# STM32N657xx register map
File version: 1.0
Registers are 32-bit, read-write, reset 0x0 unless marked. A register's access mark holds for its fields unless they carry their own. Offsets are from the block's base; [hi:lo] are bit positions; {n}, {i} and the like mark numbered series.

## PWR — Power Control
Base 0x46024800
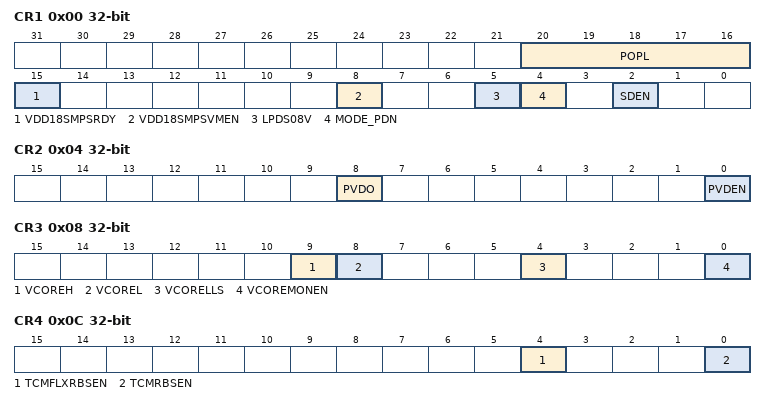
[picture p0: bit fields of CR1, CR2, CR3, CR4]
0x00 CR1 — PWR Control register 1
  [20:16] POPL — pwr_on pulse low configuration
  [15] VDD18SMPSRDY — VDD18SMPS ready
  [8] VDD18SMPSVMEN — VDD18SMPS voltage monitor enable
  [5] LPDS08V — SMPS Low power mode enable (SVOS high only)
  [4] MODE_PDN — Pull down on output voltage during power down mode
  [2] SDEN — SMPS step-down converter enable
    1=SMPS_SUPPLY (Core domains are supplied from the SMPS); 0=EXTERNAL_SOURCE_SUPPLY (The SMPS is Bypassed. The Core domains are supplied from an external source)
0x04 CR2 — PWR Control Register 2
  [8] PVDO — Programmable Voltage Detect Output
  [0] PVDEN — Programmable Voltage detector enable
0x08 CR3 — PWR Control Register 3
  [9] VCOREH — Monitored VDDCORE level above high threshold
  [8] VCOREL — Monitored VDDCORE level above low threshold
  [4] VCORELLS — VDDCORE Voltage Detector low level selection
    0=SCALE1 (VDDCORE low-voltage threshold 1 selected (VOS 1)); 1=SCALE0 (VDDCORE low-voltage threshold 2 selected (VOS 0))
  [0] VCOREMONEN — VDDCORE monitoring enable
0x0C CR4 — PWR Control Register 4
  [4] TCMFLXRBSEN — I-TCM FLEX MEM backup supply enable (used to maintain I-TCM FLEX MEM content in Standby mode)
  [0] TCMRBSEN — I-TCM and D-TCM RAMs backup supply enable (used to maintain TCM RAMs content in Standby mode)
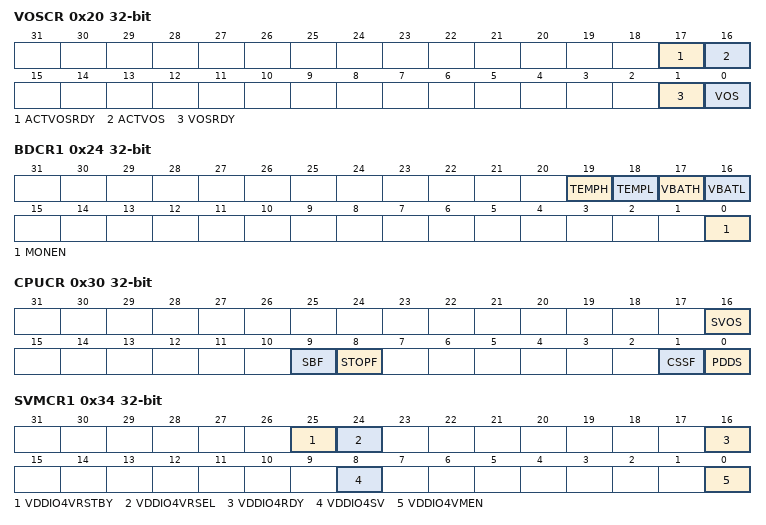
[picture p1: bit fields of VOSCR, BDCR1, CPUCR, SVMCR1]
0x20 VOSCR — PWR Voltage scaling control register
  [17] ACTVOSRDY — Voltage levels ready bit for currently used ACTVOS
  [16] ACTVOS — VOS currently applied for VCORE voltage scaling selection
  [1] VOSRDY — VOS Ready bit for VCORE voltage scaling output selection
  [0] VOS — Voltage scaling selection according to performance
    1=SCALE0 (Voltage scaling range 0 (highest frequency)); 0=SCALE1 (Voltage scaling range 1 (lowest power))
0x24 BDCR1 — PWR Backup domain control register 1
  [19] TEMPH — Temperature level monitoring versus high threshold
  [18] TEMPL — Temperature level monitoring versus low threshold
  [17] VBATH — VBAT level monitoring versus high threshold
  [16] VBATL — VBAT level monitoring versus low threshold
  [0] MONEN — VBAT and temperature monitoring enable
0x28 BDCR2 — PWR Backup domain control register 2
  [0] BKPRBSEN — Backup RAM backup supply enable (used to maintain BKP RAM content in Standby and VBAT modes)
0x2C DBPCR — PWR Disable backup protection control register
  [0] DBP — Disable backup domain write protection
0x30 CPUCR — PWR CPU control register
  [16] SVOS — System Stop mode voltage scaling selection
    1=SCALE3 (Voltage scaling range 3 (highest frequency) when system enters STOP mode); 0=SCALE5 (Voltage scaling range 5 (lowest power) when system enters STOP mode)
  [9] SBF — System Standby flag
  [8] STOPF — STOP flag
  [1] CSSF — Clear Standby and Stop flags (always read as 0)
  [0] PDDS — Power Down Deepsleep selection
    0=STOP (Enter to Stop mode when the CPU enters deepsleep); 1=STANDBY (Enter to Standby mode when the CPU enters deepsleep)
0x34 SVMCR1 — PWR Supply voltage monitoring control register 1
  [25] VDDIO4VRSTBY — VDDIO4 IO voltage range standby mode
  [24] VDDIO4VRSEL — VDDIO4 IO voltage range selection
  [16] VDDIO4RDY — VDDIO4 ready
  [8] VDDIO4SV — VDDIO4 Independent I/Os supply valid
  [0] VDDIO4VMEN — VDDOI4 Independent I/Os voltage monitor enable
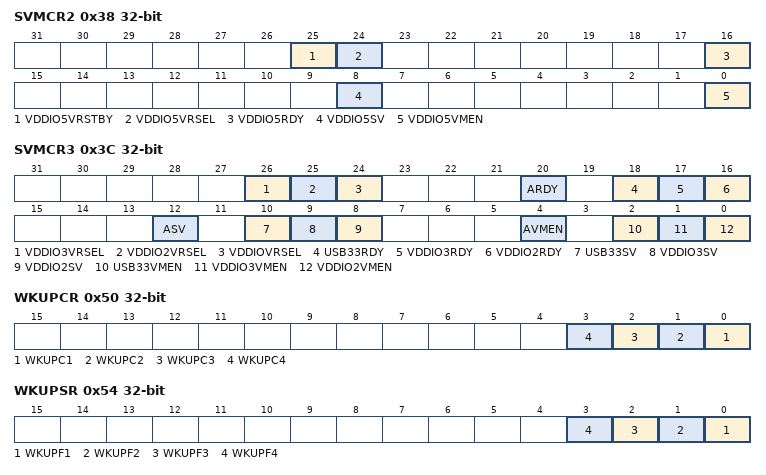
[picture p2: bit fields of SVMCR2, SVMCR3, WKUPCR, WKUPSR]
0x38 SVMCR2 — PWR Supply voltage monitoring control register 2
  [25] VDDIO5VRSTBY — VDDIO5 IO voltage range standby mode
  [24] VDDIO5VRSEL — VDDIO5 IO voltage range selection
  [16] VDDIO5RDY — VDDIO5 ready
  [8] VDDIO5SV — VDDIO5 Independent supply valid
  [0] VDDIO5VMEN — VDDIO5 Independent voltage monitor enable
0x3C SVMCR3 — PWR Supply voltage monitoring control register 3
  [26] VDDIO3VRSEL — VDDIO3 IO voltage range selection
  [25] VDDIO2VRSEL — VDDIO2 IO voltage range selection
  [24] VDDIOVRSEL — VDD IO voltage range selection
  [20] ARDY — VDDA18ADC ready
  [18] USB33RDY — VDD33USB ready
  [17] VDDIO3RDY — VDDIO3 ready
  [16] VDDIO2RDY — VDDIO2 ready
  [12] ASV — VDDA18ADC Independent supply valid
  [10] USB33SV — VDD33USB Independent supply valid
  [9] VDDIO3SV — VDDIO3 Independent supply valid
  [8] VDDIO2SV — VDDIO2 Independent supply valid
  [4] AVMEN — VDDA18ADC Independent ADC voltage monitor enable
  [2] USB33VMEN — VDD33USB Independent USB 33 voltage monitor enable
  [1] VDDIO3VMEN — VDDIO3 Independent voltage monitor enable
  [0] VDDIO2VMEN — VDDIO2 Independent voltage monitor enable
0x50 WKUPCR — PWR Wakeup control register 1
  [n-1] WKUPC{n} (n=1..4) — Clear Wakeup Flag for WKUP{n} pin
0x54 WKUPSR — PWR Wakeup control register 2
  [n-1] WKUPF{n} (n=1..4) — Wakeup Flag for WKUP{n} pin
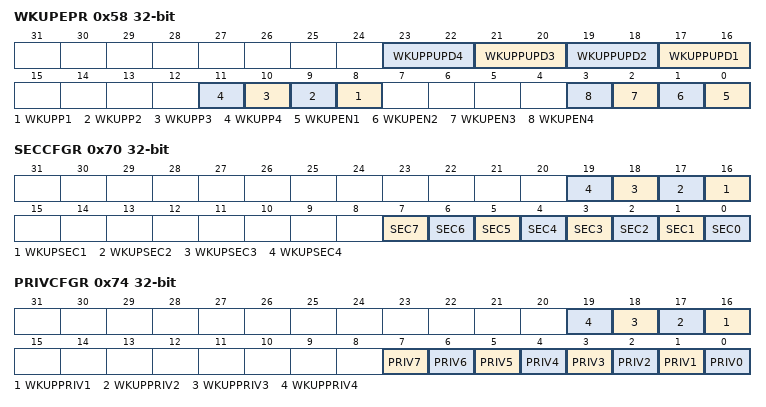
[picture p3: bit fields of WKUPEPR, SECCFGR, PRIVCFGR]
0x58 WKUPEPR — PWR Wakeup control register 3
  [2n+15:2n+14] WKUPPUPD{n} (n=1..4) — Wakeup pull configuration for WKUP{n} pin
  [n+7] WKUPP{n} (n=1..4) — Wakeup Polarity bit for WKUP{n} pin
  [n-1] WKUPEN{n} (n=1..4) — Enable Wakeup pin WKUP{n}
0x70 SECCFGR — PWR Security configuration register
  [n+15] WKUPSEC{n} (n=1..4) — WKUP{n} secure protection
  [7] SEC7 — Peripheral voltage monitor secure protection
  [6] SEC6 — CPU power control secure protection
  [5] SEC5 — Backup domain secure protection
  [4] SEC4 — Voltage scaling selection secure protection
  [3] SEC3 — I-TCM/D-TCM and I-TCM FLEX MEM low power control secure protection
  [2] SEC2 — VDDCORE monitor secure protection
  [1] SEC1 — Programmable voltage detector secure protection
  [0] SEC0 — System supply configuration secure protection
0x74 PRIVCFGR — PWR Privilege configuration register
  [n+15] WKUPPRIV{n} (n=1..4) — WKUP{n} privileged protection
  [7] PRIV7 — Peripheral voltage monitor privileged protection
  [6] PRIV6 — CPU power control privileged protection
  [5] PRIV5 — Backup domain privileged protection
  [4] PRIV4 — Voltage scaling selection privileged protection
  [3] PRIV3 — I-TCM/D-TCM and I-TCM FLEX MEM low power control privileged protection
  [2] PRIV2 — VDDCORE monitor privileged protection
  [1] PRIV1 — Programmable voltage detector privileged protection
  [0] PRIV0 — System supply configuration privileged protection
